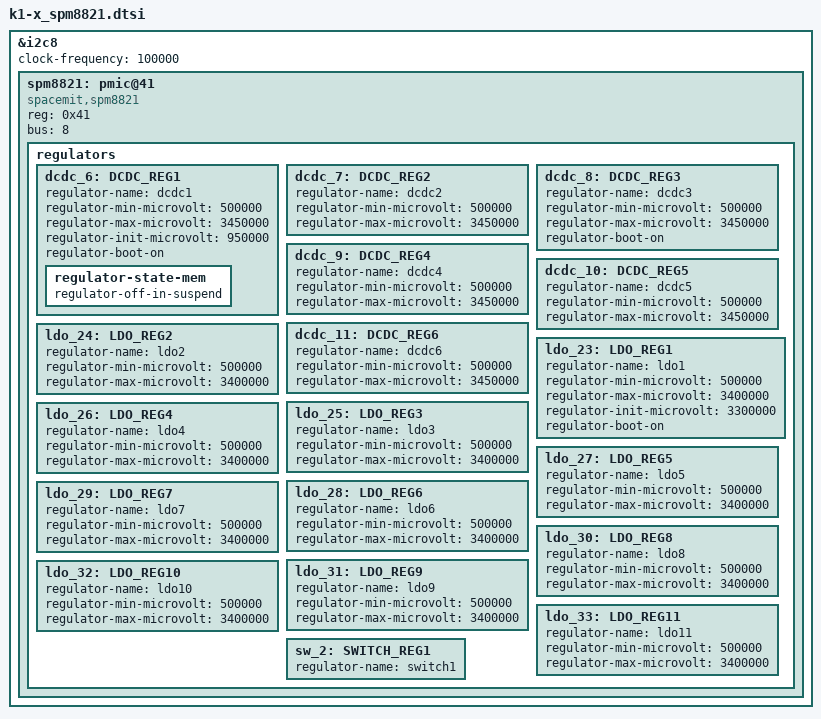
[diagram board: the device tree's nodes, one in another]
// SPDX-License-Identifier: (GPL-2.0 OR MIT)
/* Copyright (c) 2023 Spacemit, Inc */

&i2c8 {
	clock-frequency = <100000>;
	u-boot,dm-spl;
	status = "okay";

	spm8821: pmic@41 {
		compatible = "spacemit,spm8821";
		reg = <0x41>;
		bus = <8>;
		u-boot,dm-spl;

		regulators {
			/* buck */
			dcdc_6: DCDC_REG1 {
				regulator-name = "dcdc1";
				regulator-min-microvolt = <500000>;
				regulator-max-microvolt = <3450000>;
				regulator-init-microvolt = <950000>;
				regulator-boot-on;
				u-boot,dm-spl;
				regulator-state-mem {
					regulator-off-in-suspend;
				};
			};

			dcdc_7: DCDC_REG2 {
				regulator-name = "dcdc2";
				regulator-min-microvolt = <500000>;
				regulator-max-microvolt = <3450000>;
			};

			dcdc_8: DCDC_REG3 {
				regulator-name = "dcdc3";
				regulator-min-microvolt = <500000>;
				regulator-max-microvolt = <3450000>;
				regulator-boot-on;
				u-boot,dm-spl;
			};

			dcdc_9: DCDC_REG4 {
				regulator-name = "dcdc4";
				regulator-min-microvolt = <500000>;
				regulator-max-microvolt = <3450000>;
			};

			dcdc_10: DCDC_REG5 {
				regulator-name = "dcdc5";
				regulator-min-microvolt = <500000>;
				regulator-max-microvolt = <3450000>;
			};

			dcdc_11: DCDC_REG6 {
				regulator-name = "dcdc6";
				regulator-min-microvolt = <500000>;
				regulator-max-microvolt = <3450000>;
			};

			/* aldo */
			ldo_23: LDO_REG1 {
				regulator-name = "ldo1";
				regulator-min-microvolt = <500000>;
				regulator-max-microvolt = <3400000>;
				regulator-init-microvolt = <3300000>;
				regulator-boot-on;
				u-boot,dm-spl;
			};

			ldo_24: LDO_REG2 {
				regulator-name = "ldo2";
				regulator-min-microvolt = <500000>;
				regulator-max-microvolt = <3400000>;
			};

			ldo_25: LDO_REG3 {
				regulator-name = "ldo3";
				regulator-min-microvolt = <500000>;
				regulator-max-microvolt = <3400000>;
			};

			ldo_26: LDO_REG4 {
				regulator-name = "ldo4";
				regulator-min-microvolt = <500000>;
				regulator-max-microvolt = <3400000>;
			};

			/* dldo */
			ldo_27: LDO_REG5 {
				regulator-name = "ldo5";
				regulator-min-microvolt = <500000>;
				regulator-max-microvolt = <3400000>;
			};

			ldo_28: LDO_REG6 {
				regulator-name = "ldo6";
				regulator-min-microvolt = <500000>;
				regulator-max-microvolt = <3400000>;
			};

			ldo_29: LDO_REG7 {
				regulator-name = "ldo7";
				regulator-min-microvolt = <500000>;
				regulator-max-microvolt = <3400000>;
			};

			ldo_30: LDO_REG8 {
				regulator-name = "ldo8";
				regulator-min-microvolt = <500000>;
				regulator-max-microvolt = <3400000>;
			};

			ldo_31: LDO_REG9 {
				regulator-name = "ldo9";
				regulator-min-microvolt = <500000>;
				regulator-max-microvolt = <3400000>;
			};

			ldo_32: LDO_REG10 {
				regulator-name = "ldo10";
				regulator-min-microvolt = <500000>;
				regulator-max-microvolt = <3400000>;
			};

			ldo_33: LDO_REG11 {
				regulator-name = "ldo11";
				regulator-min-microvolt = <500000>;
				regulator-max-microvolt = <3400000>;
			};

			sw_2: SWITCH_REG1 {
				regulator-name = "switch1";
			};
		};
	};
};

